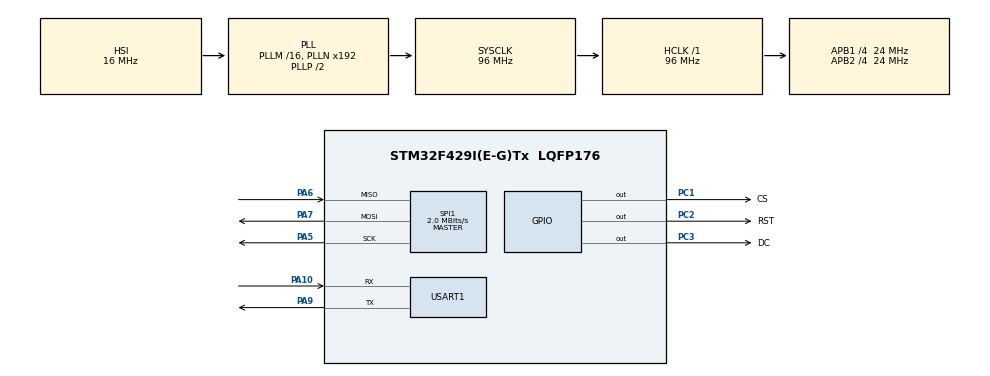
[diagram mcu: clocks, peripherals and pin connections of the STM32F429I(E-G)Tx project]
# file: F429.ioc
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Mcu.Family=STM32F4
Mcu.Name=STM32F429I(E-G)Tx
Mcu.Package=LQFP176
NVIC.PriorityGroup=NVIC_PRIORITYGROUP_4
PA10.Mode=Asynchronous
PA10.Signal=USART1_RX
PA5.Mode=Full_Duplex_Master
PA5.Signal=SPI1_SCK
PA6.Mode=Full_Duplex_Master
PA6.Signal=SPI1_MISO
PA7.Mode=Full_Duplex_Master
PA7.Signal=SPI1_MOSI
PA9.Mode=Asynchronous
PA9.Signal=USART1_TX
PC1.GPIO_Label=CS
PC1.GPIO_PuPd=GPIO_PULLDOWN
PC1.Signal=GPIO_Output
PC2.GPIO_Label=RST
PC2.GPIO_PuPd=GPIO_PULLDOWN
PC2.Signal=GPIO_Output
PC3.GPIO_Label=DC
PC3.GPIO_PuPd=GPIO_PULLDOWN
PC3.Signal=GPIO_Output
ProjectManager.HeapSize=0x200
ProjectManager.StackSize=0x400
ProjectManager.TargetToolchain=Makefile
RCC.48MHZClocksFreq_Value=48000000
RCC.AHBFreq_Value=96000000
RCC.APB1CLKDivider=RCC_HCLK_DIV4
RCC.APB1Freq_Value=24000000
RCC.APB1TimFreq_Value=48000000
RCC.APB2CLKDivider=RCC_HCLK_DIV4
RCC.APB2Freq_Value=24000000
RCC.APB2TimFreq_Value=48000000
RCC.CortexFreq_Value=96000000
RCC.HCLKFreq_Value=96000000
RCC.HSE_VALUE=25000000
RCC.HSI_VALUE=16000000
RCC.LSE_VALUE=32768
RCC.SYSCLKFreq_VALUE=96000000
RCC.SYSCLKSource=RCC_SYSCLKSOURCE_PLLCLK
RCC.VCOOutputFreq_Value=192000000
SPI1.BaudRatePrescaler=SPI_BAUDRATEPRESCALER_2
SPI1.CalculateBaudRate=2.0 MBits/s
SPI1.Direction=SPI_DIRECTION_2LINES
SPI1.Mode=SPI_MODE_MASTER
SPI1.VirtualType=VM_MASTER
USART1.VirtualMode=VM_ASYNC
board=custom

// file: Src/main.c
/* USER CODE BEGIN Header */
/**
  ******************************************************************************
  * @file           : main.c
  * @brief          : Main program body
  ******************************************************************************
  * @attention
  *
  * <h2><center>&copy; Copyright (c) 2019 STMicroelectronics.
  * All rights reserved.</center></h2>
  *
  * This software component is licensed by ST under BSD 3-Clause license,
  * the "License"; You may not use this file except in compliance with the
  * License. You may obtain a copy of the License at:
  *                        opensource.org/licenses/BSD-3-Clause
  *
  ******************************************************************************
  */
/* USER CODE END Header */

#include "main.h"
#include "mario_sprite.h"
#include "mario_jump.h"
#include "pic.h"
#include "ILI9341/ILI9341_STM32_Driver.h"
#include "ILI9341/ILI9341_GFX.h"

UART_HandleTypeDef huart1;

void SystemClock_Config(void);
static void MX_GPIO_Init(void);
static void MX_SPI1_Init(void);
static void MX_USART1_UART_Init(void);

static void HellowGarmin(void)
{

  char Greeting[5][16] = {"Hi", "Hi..","Hi...", "Hi....", "Hi....."};
  ILI9341_Set_Rotation(SCREEN_HORIZONTAL_1);
  ILI9341_Fill_Screen(ORANGE);
  for(uint8_t i = 0 ; i < 5 ; ++i)
  {
    ILI9341_Draw_Text(Greeting[i], 10, 10, BLACK, 2, ORANGE);
    HAL_Delay(1000);
  }
  ILI9341_Draw_Text("This demo program is ", 10, 25, BLACK, 2, ORANGE);
  HAL_Delay(500);
  ILI9341_Draw_Text("for Garmin interview.", 20, 40, BLACK, 2, ORANGE);
  HAL_Delay(500);
  ILI9341_Draw_Text("STM32F429 ", 10, 55, BLACK, 2, ORANGE);
  ILI9341_Draw_Text("and ILI9341.", 20, 70, BLACK, 2, ORANGE);
  HAL_Delay(500);
  ILI9341_Draw_Text("Made by Johnny Chang", 10, 220, BLACK, 2, WHITE);

}
static void Mario_Jump(uint32_t x, uint32_t y)
{
  int i = 0;
  uint32_t move_thresh[] = {10, 16, 20, 23, 25, 27 ,30 };
  ILI9341_Draw_Image(mario_bin, SCREEN_HORIZONTAL_1);
  ILI9341_Draw_Pics(mario_raw, x-16, y-21, 16 , 21);
  for( i = 0 ; i < 6 ; ++i )
  {
    ILI9341_Draw_Filled_Rectangle_Coord(x-16,y-51,x+5,y,0x547F);
    ILI9341_Draw_Pics(mario_jump_raw, x-16, y-21 - move_thresh[i], 21 , 21);
    HAL_Delay(50);
  }
  --i;
  for( ; i >= 0;i--)
  {
    ILI9341_Draw_Filled_Rectangle_Coord(x-16,y-51,x+5,y,0x547F);
    ILI9341_Draw_Pics(mario_jump_raw, x-16, y-21 - move_thresh[i], 21 , 21);
    HAL_Delay(50);
  }
  ILI9341_Draw_Filled_Rectangle_Coord(x-16,y-51,x+5,y,0x547F);
  ILI9341_Draw_Pics(mario_raw, x-16, y-21, 16 , 21);
}

int main(void)
{

  /* MCU Configuration--------------------------------------------------------*/

  /* Reset of all peripherals, Initializes the Flash interface and the Systick. */
  HAL_Init();

  /* Configure the system clock */
  SystemClock_Config();

  /* Initialize all configured peripherals */
  MX_GPIO_Init();
  MX_SPI1_Init();
  MX_USART1_UART_Init();
  /* USER CODE BEGIN 2 */
	ILI9341_Init();
  /* USER CODE END 2 */

  /* Infinite loop */
  while (1)
  {
    ILI9341_Fill_Screen(BLACK);
    HAL_Delay(1000);
    HellowGarmin();
    HAL_Delay(1000);

   while(1){
    Mario_Jump(35,221);

    HAL_Delay(1000);
    }
  }
}

void SystemClock_Config(void)
{
  RCC_OscInitTypeDef RCC_OscInitStruct = {0};
  RCC_ClkInitTypeDef RCC_ClkInitStruct = {0};

  /** Configure the main internal regulator output voltage
  */
  __HAL_RCC_PWR_CLK_ENABLE();
  __HAL_PWR_VOLTAGESCALING_CONFIG(PWR_REGULATOR_VOLTAGE_SCALE3);
  /** Initializes the CPU, AHB and APB busses clocks
  */
  RCC_OscInitStruct.OscillatorType = RCC_OSCILLATORTYPE_HSI;
  RCC_OscInitStruct.HSIState = RCC_HSI_ON;
  RCC_OscInitStruct.HSICalibrationValue = RCC_HSICALIBRATION_DEFAULT;
  RCC_OscInitStruct.PLL.PLLState = RCC_PLL_ON;
  RCC_OscInitStruct.PLL.PLLSource = RCC_PLLSOURCE_HSI;
  RCC_OscInitStruct.PLL.PLLM = 16;
  RCC_OscInitStruct.PLL.PLLN = 192;
  RCC_OscInitStruct.PLL.PLLP = RCC_PLLP_DIV2;
  RCC_OscInitStruct.PLL.PLLQ = 4;
  if (HAL_RCC_OscConfig(&RCC_OscInitStruct) != HAL_OK)
  {
    Error_Handler();
  }
  /** Initializes the CPU, AHB and APB busses clocks
  */
  RCC_ClkInitStruct.ClockType = RCC_CLOCKTYPE_HCLK|RCC_CLOCKTYPE_SYSCLK
                              |RCC_CLOCKTYPE_PCLK1|RCC_CLOCKTYPE_PCLK2;
  RCC_ClkInitStruct.SYSCLKSource = RCC_SYSCLKSOURCE_PLLCLK;
  RCC_ClkInitStruct.AHBCLKDivider = RCC_SYSCLK_DIV1;
  RCC_ClkInitStruct.APB1CLKDivider = RCC_HCLK_DIV4;
  RCC_ClkInitStruct.APB2CLKDivider = RCC_HCLK_DIV4;

  if (HAL_RCC_ClockConfig(&RCC_ClkInitStruct, FLASH_LATENCY_3) != HAL_OK)
  {
    Error_Handler();
  }
}

static void MX_SPI1_Init(void)
{

  /* SPI1 parameter configuration*/
  hspi1.Instance = SPI1;
  hspi1.Init.Mode = SPI_MODE_MASTER;
  hspi1.Init.Direction = SPI_DIRECTION_2LINES;
  hspi1.Init.DataSize = SPI_DATASIZE_8BIT;
  hspi1.Init.CLKPolarity = SPI_POLARITY_LOW;
  hspi1.Init.CLKPhase = SPI_PHASE_1EDGE;
  hspi1.Init.NSS = SPI_NSS_SOFT;
  hspi1.Init.BaudRatePrescaler = SPI_BAUDRATEPRESCALER_2;
  hspi1.Init.FirstBit = SPI_FIRSTBIT_MSB;
  hspi1.Init.TIMode = SPI_TIMODE_DISABLE;
  hspi1.Init.CRCCalculation = SPI_CRCCALCULATION_DISABLE;
  hspi1.Init.CRCPolynomial = 10;
  if (HAL_SPI_Init(&hspi1) != HAL_OK)
  {
    Error_Handler();
  }

}

static void MX_USART1_UART_Init(void)
{

  huart1.Instance = USART1;
  huart1.Init.BaudRate = 115200;
  huart1.Init.WordLength = UART_WORDLENGTH_8B;
  huart1.Init.StopBits = UART_STOPBITS_1;
  huart1.Init.Parity = UART_PARITY_NONE;
  huart1.Init.Mode = UART_MODE_TX_RX;
  huart1.Init.HwFlowCtl = UART_HWCONTROL_NONE;
  huart1.Init.OverSampling = UART_OVERSAMPLING_16;
  if (HAL_UART_Init(&huart1) != HAL_OK)
  {
    Error_Handler();
  }

}

static void MX_GPIO_Init(void)
{
  GPIO_InitTypeDef GPIO_InitStruct = {0};

  /* GPIO Ports Clock Enable */
  __HAL_RCC_GPIOC_CLK_ENABLE();
  __HAL_RCC_GPIOA_CLK_ENABLE();

  /*Configure GPIO pin Output Level */
  HAL_GPIO_WritePin(GPIOC, CS_Pin|RST_Pin|DC_Pin, GPIO_PIN_RESET);

  /*Configure GPIO pins : CS_Pin RST_Pin DC_Pin */
  GPIO_InitStruct.Pin = CS_Pin|RST_Pin|DC_Pin;
  GPIO_InitStruct.Mode = GPIO_MODE_OUTPUT_PP;
  GPIO_InitStruct.Pull = GPIO_PULLDOWN;
  GPIO_InitStruct.Speed = GPIO_SPEED_FREQ_LOW;
  HAL_GPIO_Init(GPIOC, &GPIO_InitStruct);

}

void Error_Handler(void)
{
}

/************************ (C) COPYRIGHT STMicroelectronics *****END OF FILE****/
